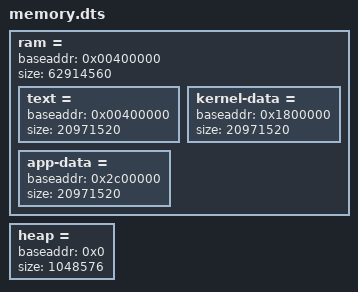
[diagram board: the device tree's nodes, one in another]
/**
 * Copyright (C) 2022 Jan Nowotsch
 * Author Jan Nowotsch	<jan.nowotsch@gmail.com>
 *
 * Released under the terms of the GNU GPL v2.0
 */



ram = {
	baseaddr = 0x00400000;
	size = 62914560;

	text = {
		baseaddr = 0x00400000;
		size = 20971520;
	};

	kernel-data = {
		baseaddr = 0x1800000;
		size = 20971520;
	};

	app-data = {
		baseaddr = 0x2c00000;
		size = 20971520;
	};
};

// The heap needs to be allocated dynamically to allow
// using it as shared memory. However, a heap node is
// needed since the kernel assumes its presence.
heap = {
	baseaddr = 0x0;
	size = 1048576;
};
